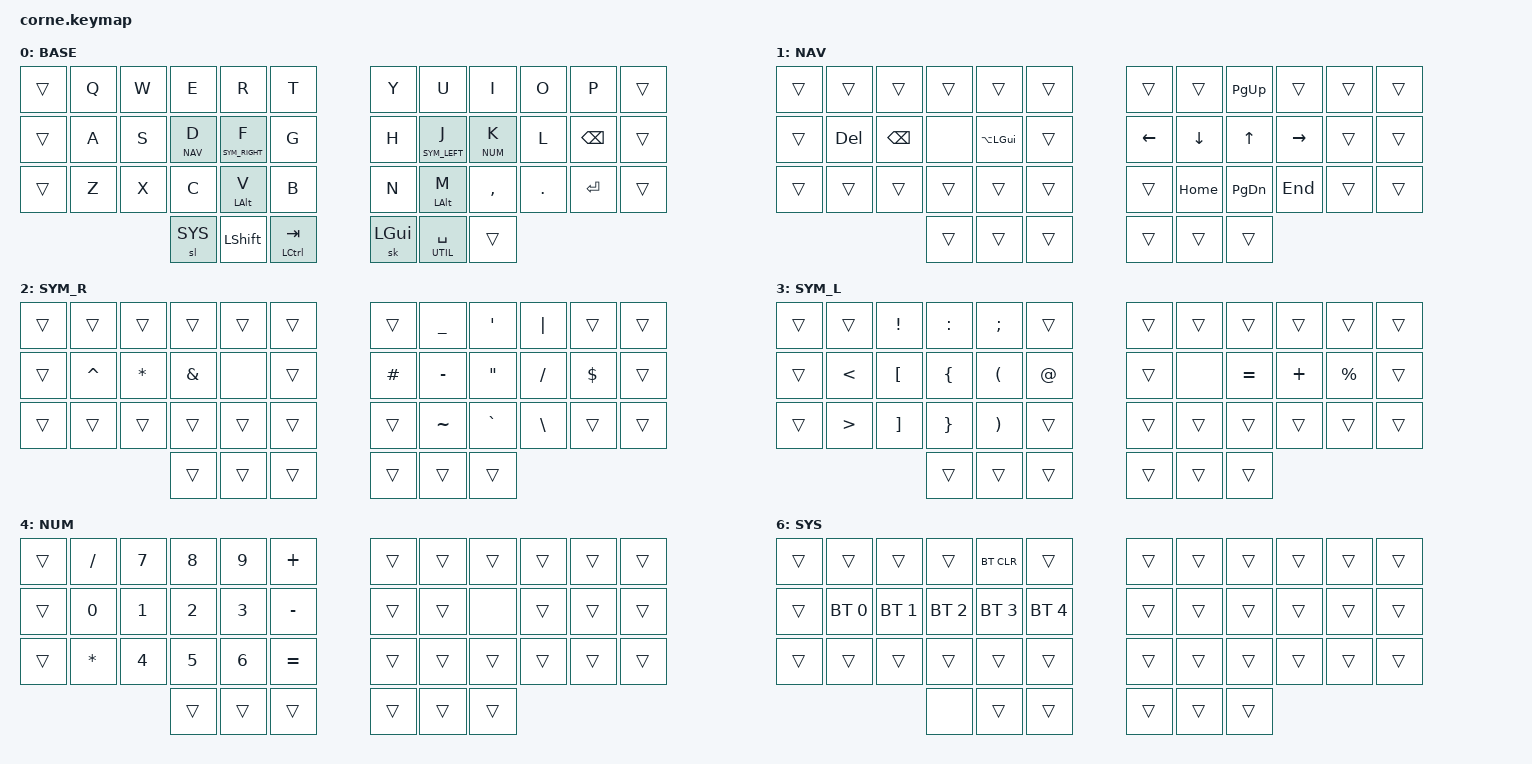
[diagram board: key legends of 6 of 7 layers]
/*
 * Copyright (c) 2020 The ZMK Contributors
 *
 * SPDX-License-Identifier: MIT
 */

#include <behaviors.dtsi>
#include <dt-bindings/zmk/keys.h>
#include <dt-bindings/zmk/bt.h>

// Layer definitions
#define BASE 0
#define NAV 1
#define SYM_RIGHT 2
#define SYM_LEFT 3
#define NUM 4
#define UTIL 5
#define SYS 6

// QMK-like keycodes
#define _XXX &none
#define ____ &trans

#define _HYPR(kc) &kp LC(LS(LA(LG(kc))))
#define _MEH(kc) &kp LC(LS(LA(kc)))

#define _RAYCAST &kp LG(SPACE)
#define _1PASS &kp LG(LS(SPACE))

&mt {
  flavor = "tap-preferred";
  tapping-term-ms = <250>;
  quick-tap-ms = <200>;
  global-quick-tap;
};

&sk {
  quick-release;
};

&lt {
  flavor = "tap-preferred";
  tapping-term-ms = <150>;
  quick-tap-ms = <200>;
};

/ {
  keymap {
    compatible = "zmk,keymap";

    base {
      label = "BASE";
      bindings = <
//        ┌──────┬───────┬───────┬───────────┬─────────────────┬────────────┐                             ┌────────────────┬────────────────┬───────────┬─────────┬───────────┬──────┐
//        │ ____ │ &kp Q │ &kp W │   &kp E   │      &kp R      │   &kp T    │                             │     &kp Y      │     &kp U      │   &kp I   │  &kp O  │   &kp P   │ ____ │
//        ├──────┼───────┼───────┼───────────┼─────────────────┼────────────┤                             ├────────────────┼────────────────┼───────────┼─────────┼───────────┼──────┤
//        │ ____ │ &kp A │ &kp S │ &lt NAV D │ &lt SYM_RIGHT F │   &kp G    │                             │     &kp H      │ &lt SYM_LEFT J │ &lt NUM K │  &kp L  │ &kp BSPC  │ ____ │
//        ├──────┼───────┼───────┼───────────┼─────────────────┼────────────┤                             ├────────────────┼────────────────┼───────────┼─────────┼───────────┼──────┤
//        │ ____ │ &kp Z │ &kp X │   &kp C   │   &mt LALT V    │   &kp B    │                             │     &kp N      │   &mt LALT M   │ &kp COMMA │ &kp DOT │ &kp ENTER │ ____ │
//        └──────┴───────┴───────┴───────────┼─────────────────┼────────────┼──────────────┐   ┌──────────┼────────────────┼────────────────┼───────────┴─────────┴───────────┴──────┘
//                                           │     &sl SYS     │ &kp LSHIFT │ &mt LCTL TAB │   │ &sk LGUI │ &lt UTIL SPACE │      ____      │                                         
//                                           └─────────────────┴────────────┴──────────────┘   └──────────┴────────────────┴────────────────┘                                         
      ____   &kp Q   &kp W   &kp E       &kp R             &kp T                                      &kp Y            &kp U            &kp I       &kp O     &kp P       ____
      ____   &kp A   &kp S   &lt NAV D   &lt SYM_RIGHT F   &kp G                                      &kp H            &lt SYM_LEFT J   &lt NUM K   &kp L     &kp BSPC    ____
      ____   &kp Z   &kp X   &kp C       &mt LALT V        &kp B                                      &kp N            &mt LALT M       &kp COMMA   &kp DOT   &kp ENTER   ____
                                         &sl SYS           &kp LSHIFT   &mt LCTL TAB       &sk LGUI   &lt UTIL SPACE   ____                                                   
      >;
    };
    nav {
      label = "NAV";
      bindings = <
//        ┌──────┬─────────┬──────────┬──────┬──────────────┬──────┐                 ┌──────────┬──────────┬───────────┬───────────┬──────┬──────┐
//        │ ____ │  ____   │   ____   │ ____ │     ____     │ ____ │                 │   ____   │   ____   │ &kp PG_UP │   ____    │ ____ │ ____ │
//        ├──────┼─────────┼──────────┼──────┼──────────────┼──────┤                 ├──────────┼──────────┼───────────┼───────────┼──────┼──────┤
//        │ ____ │ &kp DEL │ &kp BSPC │ _XXX │ &kp LA(LGUI) │ ____ │                 │ &kp LEFT │ &kp DOWN │  &kp UP   │ &kp RIGHT │ ____ │ ____ │
//        ├──────┼─────────┼──────────┼──────┼──────────────┼──────┤                 ├──────────┼──────────┼───────────┼───────────┼──────┼──────┤
//        │ ____ │  ____   │   ____   │ ____ │     ____     │ ____ │                 │   ____   │ &kp HOME │ &kp PG_DN │  &kp END  │ ____ │ ____ │
//        └──────┴─────────┴──────────┴──────┼──────────────┼──────┼──────┐   ┌──────┼──────────┼──────────┼───────────┴───────────┴──────┴──────┘
//                                           │     ____     │ ____ │ ____ │   │ ____ │   ____   │   ____   │                                      
//                                           └──────────────┴──────┴──────┘   └──────┴──────────┴──────────┘                                      
      ____   ____      ____       ____   ____           ____                     ____       ____       &kp PG_UP   ____        ____   ____
      ____   &kp DEL   &kp BSPC   _XXX   &kp LA(LGUI)   ____                     &kp LEFT   &kp DOWN   &kp UP      &kp RIGHT   ____   ____
      ____   ____      ____       ____   ____           ____                     ____       &kp HOME   &kp PG_DN   &kp END     ____   ____
                                         ____           ____   ____       ____   ____       ____                                          
      >;
    };

    sym_right {
      label = "SYM_R";
      bindings = <
//        ┌──────┬───────────┬──────────┬──────────┬──────┬──────┐                 ┌──────────┬───────────┬───────────┬──────────┬────────────┬──────┐
//        │ ____ │   ____    │   ____   │   ____   │ ____ │ ____ │                 │   ____   │ &kp UNDER │  &kp SQT  │ &kp PIPE │    ____    │ ____ │
//        ├──────┼───────────┼──────────┼──────────┼──────┼──────┤                 ├──────────┼───────────┼───────────┼──────────┼────────────┼──────┤
//        │ ____ │ &kp CARET │ &kp STAR │ &kp AMPS │ _XXX │ ____ │                 │ &kp HASH │ &kp MINUS │  &kp DQT  │ &kp FSLH │ &kp DOLLAR │ ____ │
//        ├──────┼───────────┼──────────┼──────────┼──────┼──────┤                 ├──────────┼───────────┼───────────┼──────────┼────────────┼──────┤
//        │ ____ │   ____    │   ____   │   ____   │ ____ │ ____ │                 │   ____   │ &kp TILDE │ &kp GRAVE │ &kp BSLH │    ____    │ ____ │
//        └──────┴───────────┴──────────┴──────────┼──────┼──────┼──────┐   ┌──────┼──────────┼───────────┼───────────┴──────────┴────────────┴──────┘
//                                                 │ ____ │ ____ │ ____ │   │ ____ │   ____   │   ____    │                                           
//                                                 └──────┴──────┴──────┘   └──────┴──────────┴───────────┘                                           
      ____   ____        ____       ____       ____   ____                     ____       &kp UNDER   &kp SQT     &kp PIPE   ____         ____
      ____   &kp CARET   &kp STAR   &kp AMPS   _XXX   ____                     &kp HASH   &kp MINUS   &kp DQT     &kp FSLH   &kp DOLLAR   ____
      ____   ____        ____       ____       ____   ____                     ____       &kp TILDE   &kp GRAVE   &kp BSLH   ____         ____
                                               ____   ____   ____       ____   ____       ____                                                
      >;
    };

    sym_left {
      label = "SYM_L";
      bindings = <
//        ┌──────┬────────┬──────────┬───────────┬──────────┬────────┐                 ┌──────┬──────┬─────────┬──────────┬─────────────┬──────┐
//        │ ____ │  ____  │ &kp EXCL │ &kp COLON │ &kp SEMI │  ____  │                 │ ____ │ ____ │  ____   │   ____   │    ____     │ ____ │
//        ├──────┼────────┼──────────┼───────────┼──────────┼────────┤                 ├──────┼──────┼─────────┼──────────┼─────────────┼──────┤
//        │ ____ │ &kp LT │ &kp LBKT │ &kp LBRC  │ &kp LPAR │ &kp AT │                 │ ____ │ _XXX │ &kp EQL │ &kp PLUS │ &kp PERCENT │ ____ │
//        ├──────┼────────┼──────────┼───────────┼──────────┼────────┤                 ├──────┼──────┼─────────┼──────────┼─────────────┼──────┤
//        │ ____ │ &kp GT │ &kp RBKT │ &kp RBRC  │ &kp RPAR │  ____  │                 │ ____ │ ____ │  ____   │   ____   │    ____     │ ____ │
//        └──────┴────────┴──────────┴───────────┼──────────┼────────┼──────┐   ┌──────┼──────┼──────┼─────────┴──────────┴─────────────┴──────┘
//                                               │   ____   │  ____  │ ____ │   │ ____ │ ____ │ ____ │                                          
//                                               └──────────┴────────┴──────┘   └──────┴──────┴──────┘                                          
      ____   ____     &kp EXCL   &kp COLON   &kp SEMI   ____                       ____   ____   ____      ____       ____          ____
      ____   &kp LT   &kp LBKT   &kp LBRC    &kp LPAR   &kp AT                     ____   _XXX   &kp EQL   &kp PLUS   &kp PERCENT   ____
      ____   &kp GT   &kp RBKT   &kp RBRC    &kp RPAR   ____                       ____   ____   ____      ____       ____          ____
                                             ____       ____     ____       ____   ____   ____                                          
      >;
    };

    num {
      label = "NUM";
      bindings = <
//        ┌──────┬──────────┬────────┬────────┬────────┬───────────┐                 ┌──────┬──────┬──────┬──────┬──────┬──────┐
//        │ ____ │ &kp FSLH │ &kp N7 │ &kp N8 │ &kp N9 │ &kp PLUS  │                 │ ____ │ ____ │ ____ │ ____ │ ____ │ ____ │
//        ├──────┼──────────┼────────┼────────┼────────┼───────────┤                 ├──────┼──────┼──────┼──────┼──────┼──────┤
//        │ ____ │  &kp N0  │ &kp N1 │ &kp N2 │ &kp N3 │ &kp MINUS │                 │ ____ │ ____ │ _XXX │ ____ │ ____ │ ____ │
//        ├──────┼──────────┼────────┼────────┼────────┼───────────┤                 ├──────┼──────┼──────┼──────┼──────┼──────┤
//        │ ____ │ &kp STAR │ &kp N4 │ &kp N5 │ &kp N6 │  &kp EQL  │                 │ ____ │ ____ │ ____ │ ____ │ ____ │ ____ │
//        └──────┴──────────┴────────┴────────┼────────┼───────────┼──────┐   ┌──────┼──────┼──────┼──────┴──────┴──────┴──────┘
//                                            │  ____  │   ____    │ ____ │   │ ____ │ ____ │ ____ │                            
//                                            └────────┴───────────┴──────┘   └──────┴──────┴──────┘                            
      ____   &kp FSLH   &kp N7   &kp N8   &kp N9   &kp PLUS                      ____   ____   ____   ____   ____   ____
      ____   &kp N0     &kp N1   &kp N2   &kp N3   &kp MINUS                     ____   ____   _XXX   ____   ____   ____
      ____   &kp STAR   &kp N4   &kp N5   &kp N6   &kp EQL                       ____   ____   ____   ____   ____   ____
                                          ____     ____        ____       ____   ____   ____                            
      >;
    };

    util {
      label = "UTIL";
      bindings = <
//        ┌──────┬───────────┬───────────┬───────────┬───────────┬───────────┐                        ┌──────┬──────────────────┬──────────────────────┬──────────────┬──────┬──────┐
//        │ ____ │   ____    │ &kp COLON │ &kp QMARK │ &kp EXCL  │ &kp LG(T) │                        │ ____ │   _HYPR(LEFT)    │      _HYPR(UP)       │ _HYPR(RIGHT) │ ____ │ ____ │
//        ├──────┼───────────┼───────────┼───────────┼───────────┼───────────┤                        ├──────┼──────────────────┼──────────────────────┼──────────────┼──────┼──────┤
//        │ ____ │   ____    │  _1PASS   │ _RAYCAST  │  &kp ESC  │   ____    │                        │ ____ │ &sk LC(LS(LALT)) │ &sk LG(LC(LS(LALT))) │     ____     │ ____ │ ____ │
//        ├──────┼───────────┼───────────┼───────────┼───────────┼───────────┤                        ├──────┼──────────────────┼──────────────────────┼──────────────┼──────┼──────┤
//        │ ____ │ &kp LG(Z) │ &kp LG(X) │ &kp LG(C) │ &kp LG(V) │   ____    │                        │ ____ │       ____       │         ____         │     ____     │ ____ │ ____ │
//        └──────┴───────────┴───────────┴───────────┼───────────┼───────────┼─────────────┐   ┌──────┼──────┼──────────────────┼──────────────────────┴──────────────┴──────┴──────┘
//                                                   │   ____    │   ____    │ &kp LS(TAB) │   │ ____ │ _XXX │       ____       │                                                    
//                                                   └───────────┴───────────┴─────────────┘   └──────┴──────┴──────────────────┘                                                    
      ____   ____        &kp COLON   &kp QMARK   &kp EXCL    &kp LG(T)                            ____   _HYPR(LEFT)        _HYPR(UP)              _HYPR(RIGHT)   ____   ____
      ____   ____        _1PASS      _RAYCAST    &kp ESC     ____                                 ____   &sk LC(LS(LALT))   &sk LG(LC(LS(LALT)))   ____           ____   ____
      ____   &kp LG(Z)   &kp LG(X)   &kp LG(C)   &kp LG(V)   ____                                 ____   ____               ____                   ____           ____   ____
                                                 ____        ____        &kp LS(TAB)       ____   _XXX   ____                                                                
      >;
    };

    SYS {
      label = "SYS";
      bindings = <
//        ┌──────┬──────────────┬──────────────┬──────────────┬──────────────┬──────────────┐                 ┌──────┬──────┬──────┬──────┬──────┬──────┐
//        │ ____ │     ____     │     ____     │     ____     │  &bt BT_CLR  │     ____     │                 │ ____ │ ____ │ ____ │ ____ │ ____ │ ____ │
//        ├──────┼──────────────┼──────────────┼──────────────┼──────────────┼──────────────┤                 ├──────┼──────┼──────┼──────┼──────┼──────┤
//        │ ____ │ &bt BT_SEL 0 │ &bt BT_SEL 1 │ &bt BT_SEL 2 │ &bt BT_SEL 3 │ &bt BT_SEL 4 │                 │ ____ │ ____ │ ____ │ ____ │ ____ │ ____ │
//        ├──────┼──────────────┼──────────────┼──────────────┼──────────────┼──────────────┤                 ├──────┼──────┼──────┼──────┼──────┼──────┤
//        │ ____ │     ____     │     ____     │     ____     │     ____     │     ____     │                 │ ____ │ ____ │ ____ │ ____ │ ____ │ ____ │
//        └──────┴──────────────┴──────────────┴──────────────┼──────────────┼──────────────┼──────┐   ┌──────┼──────┼──────┼──────┴──────┴──────┴──────┘
//                                                            │     _XXX     │     ____     │ ____ │   │ ____ │ ____ │ ____ │                            
//                                                            └──────────────┴──────────────┴──────┘   └──────┴──────┴──────┘                            
      ____   ____           ____           ____           &bt BT_CLR     ____                             ____   ____   ____   ____   ____   ____
      ____   &bt BT_SEL 0   &bt BT_SEL 1   &bt BT_SEL 2   &bt BT_SEL 3   &bt BT_SEL 4                     ____   ____   ____   ____   ____   ____
      ____   ____           ____           ____           ____           ____                             ____   ____   ____   ____   ____   ____
                                                          _XXX           ____           ____       ____   ____   ____                            
      >;
    };
  };
};
